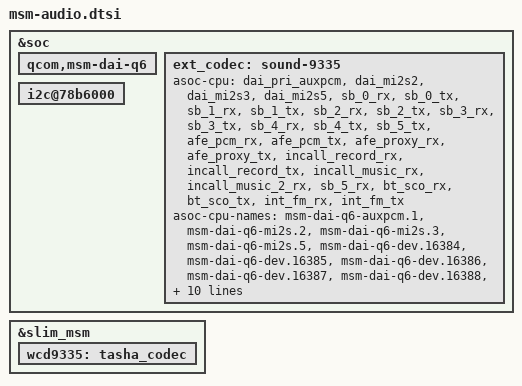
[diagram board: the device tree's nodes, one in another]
/*
 * Copyright (c) 2015-2016, The Linux Foundation. All rights reserved.
 *
 * This program is free software; you can redistribute it and/or modify
 * it under the terms of the GNU General Public License version 2 and
 * only version 2 as published by the Free Software Foundation.
 *
 * This program is distributed in the hope that it will be useful,
 * but WITHOUT ANY WARRANTY; without even the implied warranty of
 * MERCHANTABILITY or FITNESS FOR A PARTICULAR PURPOSE.  See the
 * GNU General Public License for more details.
 */

&soc {

	qcom,msm-dai-q6 {
		/delete-node/ qcom,msm-dai-q6-afe-loopback-tx;
		/delete-node/ qcom,msm-dai-q6-sb-6-rx;
	};

        ext_codec: sound-9335 {
                asoc-cpu = <&dai_pri_auxpcm>,
                                <&dai_mi2s2>, <&dai_mi2s3>, <&dai_mi2s5>,
                                <&sb_0_rx>, <&sb_0_tx>, <&sb_1_rx>, <&sb_1_tx>,
                                <&sb_2_rx>, <&sb_2_tx>, <&sb_3_rx>, <&sb_3_tx>,
                                <&sb_4_rx>, <&sb_4_tx>, <&sb_5_tx>,
                                <&afe_pcm_rx>, <&afe_pcm_tx>,
                                 <&afe_proxy_rx>, <&afe_proxy_tx>,
                                <&incall_record_rx>, <&incall_record_tx>,
                                <&incall_music_rx>, <&incall_music_2_rx>,
                                <&sb_5_rx>,  <&bt_sco_rx>,
                                <&bt_sco_tx>, <&int_fm_rx>, <&int_fm_tx>;
                asoc-cpu-names = "msm-dai-q6-auxpcm.1",
                                "msm-dai-q6-mi2s.2",
                                "msm-dai-q6-mi2s.3", "msm-dai-q6-mi2s.5",
                                "msm-dai-q6-dev.16384", "msm-dai-q6-dev.16385",
                                "msm-dai-q6-dev.16386", "msm-dai-q6-dev.16387",
                                "msm-dai-q6-dev.16388", "msm-dai-q6-dev.16389",
                                "msm-dai-q6-dev.16390", "msm-dai-q6-dev.16391",
                                "msm-dai-q6-dev.16392", "msm-dai-q6-dev.16393",
                                "msm-dai-q6-dev.16395", "msm-dai-q6-dev.224",
                                "msm-dai-q6-dev.225", "msm-dai-q6-dev.241",
                                "msm-dai-q6-dev.240", "msm-dai-q6-dev.32771",
                                "msm-dai-q6-dev.32772", "msm-dai-q6-dev.32773",
                                "msm-dai-q6-dev.32770", "msm-dai-q6-dev.16394",
                                "msm-dai-q6-dev.12288", "msm-dai-q6-dev.12289",
                                "msm-dai-q6-dev.12292", "msm-dai-q6-dev.12293";
        };


        i2c@78b6000 {
                /delete-node/ wsa881x-i2c-codec@e;
                /delete-node/ wsa881x-i2c-codec@44;
                /delete-node/ wsa881x-i2c-codec@f;
                /delete-node/ wsa881x-i2c-codec@45;
        };

};

&slim_msm {
	wcd9335: tasha_codec {
		/delete-node/ swr_master;
	};
};
